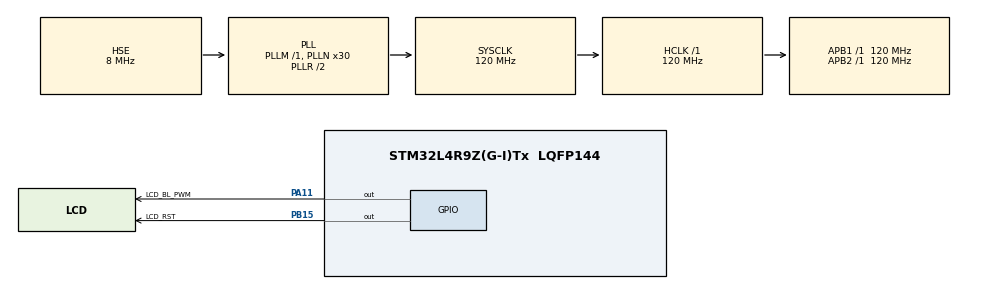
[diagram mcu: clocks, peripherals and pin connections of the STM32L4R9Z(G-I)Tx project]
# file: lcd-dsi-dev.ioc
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DSIHOST.FrameBTAAcknowledgeEnable=DSI_FBTAA_DISABLE
DSIHOST.LPCommandEnable=DSI_LP_COMMAND_DISABLE
DSIHOST.LPHorizontalBackPorchEnable=DSI_LP_HBP_ENABLE
DSIHOST.LPHorizontalFrontPorchEnable=DSI_LP_HFP_ENABLE
DSIHOST.LPLargestPacketSize=28
DSIHOST.LPVerticalActiveEnable=DSI_LP_VACT_ENABLE
DSIHOST.LPVerticalBackPorchEnable=DSI_LP_VBP_ENABLE
DSIHOST.LPVerticalFrontPorchEnable=DSI_LP_VFP_ENABLE
DSIHOST.LPVerticalSyncActiveEnable=DSI_LP_VSYNC_ENABLE
DSIHOST.Mode=DSI_VID_MODE_NB_PULSES
DSIHOST.NullPacketSize=49
DSIHOST.PacketSize=320
DSIHOST_CKN.Mode=DSIHost_Video_onelane
DSIHOST_CKN.Signal=DSIHOST_CKN
DSIHOST_CKP.Mode=DSIHost_Video_onelane
DSIHOST_CKP.Signal=DSIHOST_CKP
DSIHOST_D0N.Mode=DSIHost_Video_onelane
DSIHOST_D0N.Signal=DSIHOST_D0N
DSIHOST_D0P.Mode=DSIHost_Video_onelane
DSIHOST_D0P.Signal=DSIHOST_D0P
LTDC.ActiveW=320
LTDC.Alpha_L0=255
LTDC.FBStartAdress_L0=0x20050000
LTDC.HBP=20
LTDC.HFP=70
LTDC.HSync=3
LTDC.ImageHeight_L0=480
LTDC.ImageWidth_L0=320
LTDC.Layers=0
LTDC.PixelFormat_L0=LTDC_PIXEL_FORMAT_RGB565
LTDC.VSync=1
LTDC.WindowX1_L0=320
LTDC.WindowY1_L0=480
Mcu.Family=STM32L4
Mcu.Name=STM32L4R9Z(G-I)Tx
Mcu.Package=LQFP144
NVIC.LTDC_IRQn=true\:0\:0\:false\:false\:true\:true\:true\:true
NVIC.PriorityGroup=NVIC_PRIORITYGROUP_4
PA11.GPIO_Label=LCD_BL_PWM
PA11.PinState=GPIO_PIN_SET
PA11.Signal=GPIO_Output
PA13\ (JTMS/SWDIO).Mode=Serial_Wire
PA13\ (JTMS/SWDIO).Signal=SYS_JTMS-SWDIO
PA14\ (JTCK/SWCLK).Mode=Serial_Wire
PA14\ (JTCK/SWCLK).Signal=SYS_JTCK-SWCLK
PB15.GPIO_Label=LCD_RST
PB15.PinState=GPIO_PIN_SET
PB15.Signal=GPIO_Output
PH0-OSC_IN\ (PH0).Mode=HSE-External-Oscillator
PH0-OSC_IN\ (PH0).Signal=RCC_OSC_IN
PH1-OSC_OUT\ (PH1).Mode=HSE-External-Oscillator
PH1-OSC_OUT\ (PH1).Signal=RCC_OSC_OUT
ProjectManager.HeapSize=0x200
ProjectManager.StackSize=0x400
ProjectManager.TargetToolchain=STM32CubeIDE
RCC.ADCFreq_Value=32000000
RCC.AHBFreq_Value=120000000
RCC.APB1Freq_Value=120000000
RCC.APB1TimFreq_Value=120000000
RCC.APB2Freq_Value=120000000
RCC.APB2TimFreq_Value=120000000
RCC.CortexFreq_Value=120000000
RCC.HCLKFreq_Value=120000000
RCC.HSE_VALUE=8000000
RCC.HSI48_VALUE=48000000
RCC.HSI_VALUE=16000000
RCC.LSE_VALUE=32768
RCC.MSI_VALUE=4000000
RCC.PLLDSINDIV=32
RCC.PLLN=30
RCC.PLLSourceVirtual=RCC_PLLSOURCE_HSE
RCC.SYSCLKFreq_VALUE=120000000
RCC.SYSCLKSource=RCC_SYSCLKSOURCE_PLLCLK
RCC.USBFreq_Value=32000000
RCC.VCOOutputFreq_Value=240000000
VP_LTDC_DSIMode.Mode=RGB565
board=custom

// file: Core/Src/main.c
/* USER CODE BEGIN Header */
/**
  ******************************************************************************
  * @file           : main.c
  * @brief          : Main program body
  ******************************************************************************
  * @attention
  *
  * Copyright (c) 2024 STMicroelectronics.
  * All rights reserved.
  *
  * This software is licensed under terms that can be found in the LICENSE file
  * in the root directory of this software component.
  * If no LICENSE file comes with this software, it is provided AS-IS.
  *
  ******************************************************************************
  */
/* USER CODE END Header */
#include "main.h"

/* USER CODE BEGIN Includes */
#include "lcd.h"
/* USER CODE END Includes */

DSI_HandleTypeDef hdsi;

LTDC_HandleTypeDef hltdc;

void SystemClock_Config(void);
static void MX_GPIO_Init(void);
static void MX_DSIHOST_DSI_Init(void);
static void MX_LTDC_Init(void);

int main(void)
{

  /* MCU Configuration--------------------------------------------------------*/

  /* Reset of all peripherals, Initializes the Flash interface and the Systick. */
  HAL_Init();

  /* Configure the system clock */
  SystemClock_Config();

  /* USER CODE BEGIN SysInit */
  lcd_reset();
  /* USER CODE END SysInit */

  /* Initialize all configured peripherals */
  MX_GPIO_Init();
  MX_DSIHOST_DSI_Init();
  MX_LTDC_Init();
  /* USER CODE BEGIN 2 */

  uint16_t* ptr = (uint16_t*)0x20050000;
  for (uint32_t i = 0; i < (320 * 160); i++) {
      ptr[i] = 0xF800;
  }

  ptr = (uint16_t*)0x20050000 + 160 * 320;
  for (uint32_t i = 0; i < (320 * 160); i++) {
      ptr[i] = 0x07E0;
  }

  ptr = (uint16_t*)0x20050000 + 320 * 320;
  for (uint32_t i = 0; i < (320 * 160); i++) {
	  ptr[i] = 0x001F;
  }

  /* USER CODE END 2 */

  /* Infinite loop */
  while (1)
  {

  }
}

void SystemClock_Config(void)
{
  RCC_OscInitTypeDef RCC_OscInitStruct = {0};
  RCC_ClkInitTypeDef RCC_ClkInitStruct = {0};

  /** Configure the main internal regulator output voltage
  */
  if (HAL_PWREx_ControlVoltageScaling(PWR_REGULATOR_VOLTAGE_SCALE1_BOOST) != HAL_OK)
  {
    Error_Handler();
  }

  /** Initializes the RCC Oscillators according to the specified parameters
  * in the RCC_OscInitTypeDef structure.
  */
  RCC_OscInitStruct.OscillatorType = RCC_OSCILLATORTYPE_HSE;
  RCC_OscInitStruct.HSEState = RCC_HSE_ON;
  RCC_OscInitStruct.PLL.PLLState = RCC_PLL_ON;
  RCC_OscInitStruct.PLL.PLLSource = RCC_PLLSOURCE_HSE;
  RCC_OscInitStruct.PLL.PLLM = 1;
  RCC_OscInitStruct.PLL.PLLN = 30;
  RCC_OscInitStruct.PLL.PLLP = RCC_PLLP_DIV2;
  RCC_OscInitStruct.PLL.PLLQ = RCC_PLLQ_DIV2;
  RCC_OscInitStruct.PLL.PLLR = RCC_PLLR_DIV2;
  if (HAL_RCC_OscConfig(&RCC_OscInitStruct) != HAL_OK)
  {
    Error_Handler();
  }

  /** Initializes the CPU, AHB and APB buses clocks
  */
  RCC_ClkInitStruct.ClockType = RCC_CLOCKTYPE_HCLK|RCC_CLOCKTYPE_SYSCLK
                              |RCC_CLOCKTYPE_PCLK1|RCC_CLOCKTYPE_PCLK2;
  RCC_ClkInitStruct.SYSCLKSource = RCC_SYSCLKSOURCE_PLLCLK;
  RCC_ClkInitStruct.AHBCLKDivider = RCC_SYSCLK_DIV1;
  RCC_ClkInitStruct.APB1CLKDivider = RCC_HCLK_DIV1;
  RCC_ClkInitStruct.APB2CLKDivider = RCC_HCLK_DIV1;

  if (HAL_RCC_ClockConfig(&RCC_ClkInitStruct, FLASH_LATENCY_5) != HAL_OK)
  {
    Error_Handler();
  }
}

static void MX_DSIHOST_DSI_Init(void)
{

  DSI_PLLInitTypeDef PLLInit = {0};
  DSI_HOST_TimeoutTypeDef HostTimeouts = {0};
  DSI_PHY_TimerTypeDef PhyTimings = {0};
  DSI_VidCfgTypeDef VidCfg = {0};

  hdsi.Instance = DSI;
  hdsi.Init.AutomaticClockLaneControl = DSI_AUTO_CLK_LANE_CTRL_DISABLE;
  hdsi.Init.TXEscapeCkdiv = 4;
  hdsi.Init.NumberOfLanes = DSI_ONE_DATA_LANE;
  PLLInit.PLLNDIV = 32;
  PLLInit.PLLIDF = DSI_PLL_IN_DIV1;
  PLLInit.PLLODF = DSI_PLL_OUT_DIV1;
  if (HAL_DSI_Init(&hdsi, &PLLInit) != HAL_OK)
  {
    Error_Handler();
  }
  HostTimeouts.TimeoutCkdiv = 1;
  HostTimeouts.HighSpeedTransmissionTimeout = 0;
  HostTimeouts.LowPowerReceptionTimeout = 0;
  HostTimeouts.HighSpeedReadTimeout = 0;
  HostTimeouts.LowPowerReadTimeout = 0;
  HostTimeouts.HighSpeedWriteTimeout = 0;
  HostTimeouts.HighSpeedWritePrespMode = DSI_HS_PM_DISABLE;
  HostTimeouts.LowPowerWriteTimeout = 0;
  HostTimeouts.BTATimeout = 0;
  if (HAL_DSI_ConfigHostTimeouts(&hdsi, &HostTimeouts) != HAL_OK)
  {
    Error_Handler();
  }
  PhyTimings.ClockLaneHS2LPTime = 20;
  PhyTimings.ClockLaneLP2HSTime = 18;
  PhyTimings.DataLaneHS2LPTime = 10;
  PhyTimings.DataLaneLP2HSTime = 13;
  PhyTimings.DataLaneMaxReadTime = 0;
  PhyTimings.StopWaitTime = 0;
  if (HAL_DSI_ConfigPhyTimer(&hdsi, &PhyTimings) != HAL_OK)
  {
    Error_Handler();
  }
  if (HAL_DSI_ConfigFlowControl(&hdsi, DSI_FLOW_CONTROL_BTA) != HAL_OK)
  {
    Error_Handler();
  }
  if (HAL_DSI_SetLowPowerRXFilter(&hdsi, 10000) != HAL_OK)
  {
    Error_Handler();
  }
  if (HAL_DSI_ConfigErrorMonitor(&hdsi, HAL_DSI_ERROR_NONE) != HAL_OK)
  {
    Error_Handler();
  }
  VidCfg.VirtualChannelID = 0;
  VidCfg.ColorCoding = DSI_RGB565;
  VidCfg.LooselyPacked = DSI_LOOSELY_PACKED_DISABLE;
  VidCfg.Mode = DSI_VID_MODE_NB_PULSES;
  VidCfg.PacketSize = 320;
  VidCfg.NumberOfChunks = 1;
  VidCfg.NullPacketSize = 49;
  VidCfg.HSPolarity = DSI_HSYNC_ACTIVE_LOW;
  VidCfg.VSPolarity = DSI_VSYNC_ACTIVE_LOW;
  VidCfg.DEPolarity = DSI_DATA_ENABLE_ACTIVE_HIGH;
  VidCfg.HorizontalSyncActive = 6;
  VidCfg.HorizontalBackPorch = 40;
  VidCfg.HorizontalLine = 826;
  VidCfg.VerticalSyncActive = 1;
  VidCfg.VerticalBackPorch = 2;
  VidCfg.VerticalFrontPorch = 2;
  VidCfg.VerticalActive = 480;
  VidCfg.LPCommandEnable = DSI_LP_COMMAND_DISABLE;
  VidCfg.LPLargestPacketSize = 28;
  VidCfg.LPVACTLargestPacketSize = 0;
  VidCfg.LPHorizontalFrontPorchEnable = DSI_LP_HFP_ENABLE;
  VidCfg.LPHorizontalBackPorchEnable = DSI_LP_HBP_ENABLE;
  VidCfg.LPVerticalActiveEnable = DSI_LP_VACT_ENABLE;
  VidCfg.LPVerticalFrontPorchEnable = DSI_LP_VFP_ENABLE;
  VidCfg.LPVerticalBackPorchEnable = DSI_LP_VBP_ENABLE;
  VidCfg.LPVerticalSyncActiveEnable = DSI_LP_VSYNC_ENABLE;
  VidCfg.FrameBTAAcknowledgeEnable = DSI_FBTAA_DISABLE;
  if (HAL_DSI_ConfigVideoMode(&hdsi, &VidCfg) != HAL_OK)
  {
    Error_Handler();
  }
  if (HAL_DSI_SetGenericVCID(&hdsi, 0) != HAL_OK)
  {
    Error_Handler();
  }
  /* USER CODE BEGIN DSIHOST_Init 2 */
  if (HAL_DSI_Start(&hdsi) != HAL_OK)
  {
    Error_Handler();
  }
  /* USER CODE END DSIHOST_Init 2 */

}

static void MX_LTDC_Init(void)
{

  LTDC_LayerCfgTypeDef pLayerCfg = {0};

  hltdc.Instance = LTDC;
  hltdc.Init.HSPolarity = LTDC_HSPOLARITY_AL;
  hltdc.Init.VSPolarity = LTDC_VSPOLARITY_AL;
  hltdc.Init.DEPolarity = LTDC_DEPOLARITY_AL;
  hltdc.Init.PCPolarity = LTDC_PCPOLARITY_IPC;
  hltdc.Init.HorizontalSync = 2;
  hltdc.Init.VerticalSync = 0;
  hltdc.Init.AccumulatedHBP = 22;
  hltdc.Init.AccumulatedVBP = 2;
  hltdc.Init.AccumulatedActiveW = 342;
  hltdc.Init.AccumulatedActiveH = 482;
  hltdc.Init.TotalWidth = 412;
  hltdc.Init.TotalHeigh = 484;
  hltdc.Init.Backcolor.Blue = 0;
  hltdc.Init.Backcolor.Green = 0;
  hltdc.Init.Backcolor.Red = 0;
  if (HAL_LTDC_Init(&hltdc) != HAL_OK)
  {
    Error_Handler();
  }
  pLayerCfg.WindowX0 = 0;
  pLayerCfg.WindowX1 = 320;
  pLayerCfg.WindowY0 = 0;
  pLayerCfg.WindowY1 = 480;
  pLayerCfg.PixelFormat = LTDC_PIXEL_FORMAT_RGB565;
  pLayerCfg.Alpha = 255;
  pLayerCfg.Alpha0 = 0;
  pLayerCfg.BlendingFactor1 = LTDC_BLENDING_FACTOR1_CA;
  pLayerCfg.BlendingFactor2 = LTDC_BLENDING_FACTOR2_CA;
  pLayerCfg.FBStartAdress = 0x20050000;
  pLayerCfg.ImageWidth = 320;
  pLayerCfg.ImageHeight = 480;
  pLayerCfg.Backcolor.Blue = 0;
  pLayerCfg.Backcolor.Green = 0;
  pLayerCfg.Backcolor.Red = 0;
  if (HAL_LTDC_ConfigLayer(&hltdc, &pLayerCfg, 0) != HAL_OK)
  {
    Error_Handler();
  }
  /* USER CODE BEGIN LTDC_Init 2 */
  uint8_t cmd_e0[] = {0x0D, 0x13, 0x14, 0x01, 0x0C, 0x03, 0x31, 0x46, 0x45, 0x03, 0x0C, 0x0A, 0x2A, 0x30, 0x0D};
  HAL_DSI_LongWrite(&hdsi, 0, DSI_DCS_LONG_PKT_WRITE, sizeof(cmd_e0), 0xE0, cmd_e0);
  uint8_t cmd_e1[] = {0x0A, 0x10, 0x16, 0x05, 0x12, 0x08, 0x3D, 0x45, 0x53, 0x07, 0x11, 0x0E, 0x30, 0x33, 0x0A};
  HAL_DSI_LongWrite(&hdsi, 0, DSI_DCS_LONG_PKT_WRITE, sizeof(cmd_e1), 0xE1, cmd_e1);
  uint8_t cmd_c0[] = {0x0A, 0x0A};
  HAL_DSI_LongWrite(&hdsi, 0, DSI_DCS_LONG_PKT_WRITE, sizeof(cmd_c0), 0xC0, cmd_c0);
  HAL_DSI_ShortWrite(&hdsi, 0, DSI_DCS_SHORT_PKT_WRITE_P1, 0xC1, 0x41);
  uint8_t cmd_c5[] = {0x00, 0x25, 0x80};
  HAL_DSI_LongWrite(&hdsi, 0, DSI_DCS_LONG_PKT_WRITE, sizeof(cmd_c5), 0xC5, cmd_c5);
  HAL_DSI_ShortWrite(&hdsi, 0, DSI_DCS_SHORT_PKT_WRITE_P1, 0x36, 0x48);
  HAL_DSI_ShortWrite(&hdsi, 0, DSI_DCS_SHORT_PKT_WRITE_P1, 0x3A, 0x55);
  HAL_DSI_ShortWrite(&hdsi, 0, DSI_DCS_SHORT_PKT_WRITE_P1, 0xF8, 0x05);
  uint8_t cmd_b1[] = {0xA0, 0x11};
  HAL_DSI_LongWrite(&hdsi, 0, DSI_DCS_LONG_PKT_WRITE, sizeof(cmd_b1), 0xB1, cmd_b1);
  HAL_DSI_ShortWrite(&hdsi, 0, DSI_DCS_SHORT_PKT_WRITE_P1, 0xB4, 0x02);
  uint8_t cmd_b6[] = {0x82, 0x22, 0x3B};
  HAL_DSI_LongWrite(&hdsi, 0, DSI_DCS_LONG_PKT_WRITE, sizeof(cmd_b6), 0xB6, cmd_b6);
  HAL_DSI_ShortWrite(&hdsi, 0, DSI_DCS_SHORT_PKT_WRITE_P1, 0xE9, 0x01);
  uint8_t cmd_f7[] = {0xA9, 0x51, 0x2C, 0x82};
  HAL_DSI_LongWrite(&hdsi, 0, DSI_DCS_LONG_PKT_WRITE, sizeof(cmd_f7), 0xF7, cmd_f7);
  HAL_DSI_ShortWrite(&hdsi, 0, DSI_DCS_SHORT_PKT_WRITE_P0, 0x21, 0x00);
  HAL_DSI_ShortWrite(&hdsi, 0, DSI_DCS_SHORT_PKT_WRITE_P0, DSI_EXIT_SLEEP_MODE, 0x00);
  HAL_Delay(120);
  HAL_DSI_ShortWrite(&hdsi, 0, DSI_DCS_SHORT_PKT_WRITE_P0, DSI_SET_DISPLAY_ON, 0x00);
  HAL_Delay(100);
//  lcd_init();
  /* USER CODE END LTDC_Init 2 */

}

static void MX_GPIO_Init(void)
{
  GPIO_InitTypeDef GPIO_InitStruct = {0};

  /* GPIO Ports Clock Enable */
  __HAL_RCC_GPIOH_CLK_ENABLE();
  __HAL_RCC_GPIOB_CLK_ENABLE();
  __HAL_RCC_GPIOA_CLK_ENABLE();

  /*Configure GPIO pin Output Level */
  HAL_GPIO_WritePin(LCD_RST_GPIO_Port, LCD_RST_Pin, GPIO_PIN_SET);

  /*Configure GPIO pin Output Level */
  HAL_GPIO_WritePin(LCD_BL_PWM_GPIO_Port, LCD_BL_PWM_Pin, GPIO_PIN_SET);

  /*Configure GPIO pin : LCD_RST_Pin */
  GPIO_InitStruct.Pin = LCD_RST_Pin;
  GPIO_InitStruct.Mode = GPIO_MODE_OUTPUT_PP;
  GPIO_InitStruct.Pull = GPIO_NOPULL;
  GPIO_InitStruct.Speed = GPIO_SPEED_FREQ_LOW;
  HAL_GPIO_Init(LCD_RST_GPIO_Port, &GPIO_InitStruct);

  /*Configure GPIO pin : LCD_BL_PWM_Pin */
  GPIO_InitStruct.Pin = LCD_BL_PWM_Pin;
  GPIO_InitStruct.Mode = GPIO_MODE_OUTPUT_PP;
  GPIO_InitStruct.Pull = GPIO_NOPULL;
  GPIO_InitStruct.Speed = GPIO_SPEED_FREQ_LOW;
  HAL_GPIO_Init(LCD_BL_PWM_GPIO_Port, &GPIO_InitStruct);

}

void Error_Handler(void)
{
  __disable_irq();
  while (1)
  {
  }
}
